# EFR32MG21A010F1024IM32 register map
Vendor: Silicon Labs; Series: EFR32; File version: B
Registers are 32-bit, read-write, reset 0x0 unless marked. A register's access mark holds for its fields unless they carry their own. Offsets are from the block's base; [hi:lo] are bit positions.

## CMU_S — CMU_S Registers
Base 0x40008000
Same registers: CMU_NS 0x50008000
0x00 IPVERSION ro
  [31:0] IPVERSION — IP Version ID
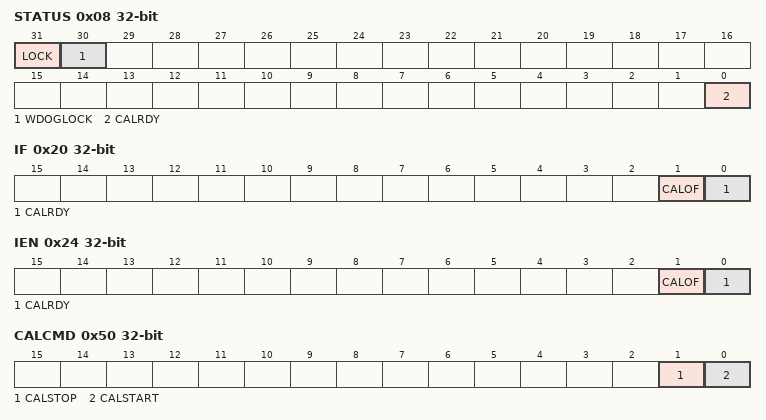
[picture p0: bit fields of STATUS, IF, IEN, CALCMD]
0x08 STATUS ro
  [31] LOCK — Configuration Lock Status
    0=UNLOCKED; 1=LOCKED
  [30] WDOGLOCK — Configuration Lock Status for WDOG
    0=UNLOCKED; 1=LOCKED
  [0] CALRDY — Calibration Ready
0x10 LOCK wo reset 0x93F7
  [15:0] LOCKKEY — Configuration Lock Key
    0x93F7=UNLOCK
0x14 WDOGLOCK wo reset 0x5257
  [15:0] LOCKKEY — Configuration Lock Key
    0x93F7=UNLOCK
0x20 IF
  [1] CALOF — Calibration Overflow Interrupt Flag
  [0] CALRDY — Calibration Ready Interrupt Flag
0x24 IEN
  [1] CALOF — Calibration Overflow Interrupt Enable
  [0] CALRDY — Calibration Ready Interrupt Enable
0x50 CALCMD wo
  [1] CALSTOP — Calibration Stop
  [0] CALSTART — Calibration Start
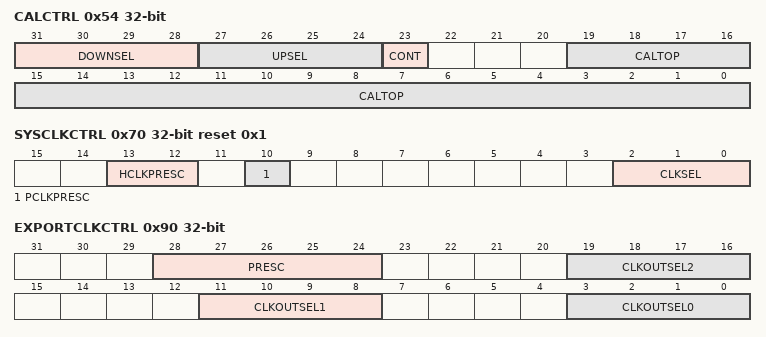
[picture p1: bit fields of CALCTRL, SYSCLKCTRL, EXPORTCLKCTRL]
0x54 CALCTRL
  [31:28] DOWNSEL — Calibration Down-counter Select
    0=DISABLED (Down-counter is not clocked); 1=HCLK (HCLK is clocking down-counter); 2=PRS (PRS CMU_CALDN consumer is clocking down-counter); 3=HFXO (HFXO is clocking down-counter); 4=LFXO (LFXO is clocking down-counter); 5=HFRCODPLL (HFRCODPLL is clocking down-counter); 6=HFRCOEM23 (HFRCOEM23 is clocking down-counter); 9=FSRCO (FSRCO is clocking down-counter); 10=LFRCO (LFRCO is clocking down-counter); 11=ULFRCO (ULFRCO is clocking down-counter)
  [27:24] UPSEL — Calibration Up-counter Select
    0=DISABLED (Up-counter is not clocked); 1=PRS (PRS CMU_CALUP consumer is clocking up-counter); 2=HFXO (HFXO is clocking up-counter); 3=LFXO (LFXO is clocking up-counter); 4=HFRCODPLL (HFRCODPLL is clocking up-counter); 5=HFRCOEM23 (HFRCOEM23 is clocking up-counter); 8=FSRCO (FSRCO is clocking up-counter); 9=LFRCO (LFRCO is clocking up-counter); 10=ULFRCO (ULFRCO is clocking up-counter)
  [23] CONT — Continuous Calibration
  [19:0] CALTOP — Calibration Counter Top Value
0x58 CALCNT ro
  [19:0] CALCNT — Calibration Result Counter Value
0x70 SYSCLKCTRL reset 0x1
  [13:12] HCLKPRESC — HCLK Prescaler
    0=DIV1 (HCLK is SYSCLK divided by 1); 1=DIV2 (HCLK is SYSCLK divided by 2); 3=DIV4 (HCLK is SYSCLK divided by 4)
  [10] PCLKPRESC — PCLK Prescaler
    0=DIV1 (PCLK is HCLK divided by 1); 1=DIV2 (PCLK is HCLK divided by 2)
  [2:0] CLKSEL — Clock Select
    1=FSRCO (FSRCO is clocking SYSCLK); 2=HFRCODPLL (HFRCODPLL is clocking SYSCLK); 3=HFXO (HFXO is clocking SYSCLK); 4=CLKIN0 (CLKIN0 is clocking SYSCLK)
0x80 TRACECLKCTRL reset 0x1
  [1:0] CLKSEL — Clock Select
    2=HCLK (HCLK is clocking TRACECLK); 3=HFRCOEM23 (HFRCOEM23 is clocking TRACECLK)
0x90 EXPORTCLKCTRL
  [28:24] PRESC — EXPORTCLK Prescaler
  [19:16] CLKOUTSEL2 — Clock Output Select 2
    0=DISABLED (CLKOUT2 is not clocked); 1=HCLK (HCLK is clocking CLKOUT2); 2=HFEXPCLK (EXPORTCLK is clocking CLKOUT2); 3=ULFRCO (ULFRCO is clocking CLKOUT2); 4=LFRCO (LFRCO is clocking CLKOUT2); 5=LFXO (LFXO is clocking CLKOUT2); 6=HFRCODPLL (HFRCODPLL is clocking CLKOUT2); 7=HFRCOEM23 (HFRCOEM23 is clocking CLKOUT2); 8=HFXO (HFXO is clocking CLKOUT2); 9=FSRCO (FSRCO is clocking CLKOUT2)
  [11:8] CLKOUTSEL1 — Clock Output Select 1
    0=DISABLED (CLKOUT1 is not clocked); 1=HCLK (HCLK is clocking CLKOUT1); 2=HFEXPCLK (EXPORTCLK is clocking CLKOUT1); 3=ULFRCO (ULFRCO is clocking CLKOUT1); 4=LFRCO (LFRCO is clocking CLKOUT1); 5=LFXO (LFXO is clocking CLKOUT1); 6=HFRCODPLL (HFRCODPLL is clocking CLKOUT1); 7=HFRCOEM23 (HFRCOEM23 is clocking CLKOUT1); 8=HFXO (HFXO is clocking CLKOUT1); 9=FSRCO (FSRCO is clocking CLKOUT1)
  [3:0] CLKOUTSEL0 — Clock Output Select 0
    0=DISABLED (CLKOUT0 is not clocked); 1=HCLK (HCLK is clocking CLKOUT0); 2=HFEXPCLK (EXPORTCLK is clocking CLKOUT0); 3=ULFRCO (ULFRCO is clocking CLKOUT0); 4=LFRCO (LFRCO is clocking CLKOUT0); 5=LFXO (LFXO is clocking CLKOUT0); 6=HFRCODPLL (HFRCODPLL is clocking CLKOUT0); 7=HFRCOEM23 (HFRCOEM23 is clocking CLKOUT0); 8=HFXO (HFXO is clocking CLKOUT0); 9=FSRCO (FSRCO is clocking CLKOUT0)
0x100 DPLLREFCLKCTRL
  [1:0] CLKSEL — Clock Select
    0=DISABLED (DPLLREFCLK is not clocked); 1=HFXO (HFXO is clocking DPLLREFCLK); 2=LFXO (LFXO is clocking DPLLREFCLK); 3=CLKIN0 (CLKIN0 is clocking DPLLREFCLK)
0x120 EM01GRPACLKCTRL reset 0x1
  [2:0] CLKSEL — Clock Select
    1=HFRCODPLL (HFRCODPLL is clocking EM01GRPACLK); 2=HFXO (HFXO is clocking EM01GRPACLK); 3=HFRCOEM23 (HFRCOEM23 is clocking EM01GRPACLK); 4=FSRCO (FSRCO is clocking EM01GRPACLK)
0x140 EM23GRPACLKCTRL reset 0x1
  [1:0] CLKSEL — Clock Select
    1=LFRCO (LFRCO is clocking EM23GRPACLK); 2=LFXO (LFXO is clocking EM23GRPACLK); 3=ULFRCO (ULFRCO is clocking EM23GRPACLK)
0x160 EM4GRPACLKCTRL reset 0x1
  [1:0] CLKSEL — Clock Select
    1=LFRCO (LFRCO is clocking EM4GRPACLK); 2=LFXO (LFXO is clocking EM4GRPACLK); 3=ULFRCO (ULFRCO is clocking EM4GRPACLK)
0x180 IADCCLKCTRL reset 0x1
  [1:0] CLKSEL — Clock Select
    1=EM01GRPACLK (EM01GRPACLK is clocking IADCCLK); 2=HFRCOEM23 (HFRCOEM23 is clocking IADCCLK); 3=FSRCO (FSRCO is clocking IADCCLK)
0x200 WDOG0CLKCTRL reset 0x1
  [2:0] CLKSEL — Clock Select
    1=LFRCO (LFRCO is clocking WDOG0CLK); 2=LFXO (LFXO is clocking WDOG0CLK); 3=ULFRCO (ULFRCO is clocking WDOG0CLK); 4=HCLKDIV1024 (HCLKDIV1024 is clocking WDOG0CLK)
0x208 WDOG1CLKCTRL reset 0x1
  [2:0] CLKSEL — Clock Select
    1=LFRCO (LFRCO is clocking WDOG1CLK); 2=LFXO (LFXO is clocking WDOG1CLK); 3=ULFRCO (ULFRCO is clocking WDOG1CLK); 4=HCLKDIV1024 (HCLKDIV1024 is clocking WDOG1CLK)
0x240 RTCCCLKCTRL reset 0x1
  [1:0] CLKSEL — Clock Select
    1=LFRCO (LFRCO is clocking RTCCCLK); 2=LFXO (LFXO is clocking RTCCCLK); 3=ULFRCO (ULFRCO is clocking RTCCCLK)
0x248 PRORTCCLKCTRL reset 0x1
  [1:0] CLKSEL — Clock Select
    1=LFRCO (LFRCO is clocking PRORTCCLK); 2=LFXO (LFXO is clocking PRORTCCLK); 3=ULFRCO (ULFRCO is clocking PRORTCCLK)
0x280 RADIOCLKCTRL
  [0] EN — Enable
